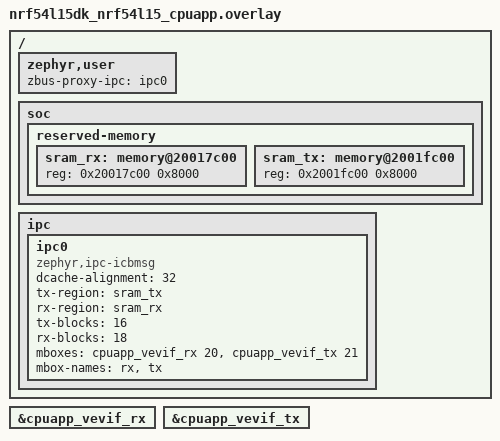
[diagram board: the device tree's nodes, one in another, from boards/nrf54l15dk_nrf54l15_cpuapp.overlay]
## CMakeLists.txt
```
#
# Copyright (c) 2026 Nordic Semiconductor ASA
#
# SPDX-License-Identifier: Apache-2.0
#

cmake_minimum_required(VERSION 3.28.0)

find_package(Zephyr REQUIRED HINTS $ENV{ZEPHYR_BASE})
project(zbus_ipc_forwarder)

zephyr_library_include_directories(src)

target_sources(app PRIVATE src/main.c)
```

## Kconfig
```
#
# Copyright (c) 2026 Nordic Semiconductor ASA
#
# SPDX-License-Identifier: Apache-2.0
#

source "Kconfig.zephyr"
```

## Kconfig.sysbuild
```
#
# Copyright (c) 2026 Nordic Semiconductor ASA
#
# SPDX-License-Identifier: Apache-2.0
#

source "share/sysbuild/Kconfig"

choice
	prompt "Remote board target"
	default REMOTE_BOARD_NRF54H20_CPURAD if BOARD = "nrf54h20dk"
	default REMOTE_BOARD_NRF54LM20A_CPUFLPR if BOARD = "nrf54lm20dk"
	default REMOTE_BOARD_NRF54L15_CPUFLPR if BOARD = "nrf54l15dk"
	default REMOTE_BOARD_NRF5340_CPUNET if BOARD = "nrf5340dk"
	default REMOTE_BOARD_ESP32_DEVKITC_ESP32_APPCPU if BOARD = "esp32_devkitc"
	default REMOTE_BOARD_ESP32S3_DEVKITC_ESP32S3_APPCPU if BOARD = "esp32s3_devkitc"

config REMOTE_BOARD_NRF54H20_CPURAD
	bool "nrf54h20dk/nrf54h20/cpurad"

config REMOTE_BOARD_NRF54LM20A_CPUFLPR
	bool "nrf54lm20dk/nrf54lm20a/cpuflpr"

config REMOTE_BOARD_NRF54L15_CPUFLPR
	bool "nrf54l15dk/nrf54l15/cpuflpr"

config REMOTE_BOARD_NRF5340_CPUNET
	bool "nrf5340dk/nrf5340/cpunet"

config REMOTE_BOARD_ESP32_DEVKITC_ESP32_APPCPU
	bool "esp32_devkitc/esp32/appcpu"

config REMOTE_BOARD_ESP32S3_DEVKITC_ESP32S3_APPCPU
	bool "esp32s3_devkitc/esp32s3/appcpu"

endchoice

config REMOTE_BOARD
	string "The board used for remote target"
	default "nrf54h20dk/nrf54h20/cpurad" if REMOTE_BOARD_NRF54H20_CPURAD
	default "nrf54l15dk/nrf54l15/cpuflpr" if REMOTE_BOARD_NRF54L15_CPUFLPR
	default "nrf54lm20dk/nrf54lm20a/cpuflpr" if REMOTE_BOARD_NRF54LM20A_CPUFLPR
	default "nrf5340dk/nrf5340/cpunet" if REMOTE_BOARD_NRF5340_CPUNET
	default "esp32_devkitc/esp32/appcpu" if REMOTE_BOARD_ESP32_DEVKITC_ESP32_APPCPU
	default "esp32s3_devkitc/esp32s3/appcpu" if REMOTE_BOARD_ESP32S3_DEVKITC_ESP32S3_APPCPU
```

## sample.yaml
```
sample:
  name: IPC Forwarder
  description: Sample application demonstrating Zbus IPC forwarder functionality.
common:
  tags:
    - zbus
  harness: console
  harness_config:
    type: multi_line
    ordered: true
    regex:
      - ".* ZBUS Proxy agent IPC Forwarder Sample Application"
      - ".* Requesting on channel request_channel, listening on channel response_channel"
      - ".* Published on channel request_channel. Test Value=1"
      - ".* Received message on channel response_channel. Test Value=2"

tests:
  sample.zbus.proxy_agent_ipc.nrf54h20_cpuapp_cpurad:
    sysbuild: true
    platform_allow:
      - nrf54h20dk/nrf54h20/cpuapp

  sample.zbus.proxy_agent_ipc.nrf54lm20_cpuapp_cpuflpr:
    sysbuild: true
    platform_allow:
      - nrf54lm20dk/nrf54lm20a/cpuapp
    extra_args:
      - proxy_agent_ipc_SNIPPET=nordic-flpr

  sample.zbus.proxy_agent_ipc.nrf54l15_cpuapp_cpuflpr:
    sysbuild: true
    platform_allow:
      - nrf54l15dk/nrf54l15/cpuapp
    extra_args:
      - proxy_agent_ipc_SNIPPET=nordic-flpr

  sample.zbus.proxy_agent_ipc.nrf5340_cpuapp_cpunet:
    sysbuild: true
    platform_allow:
      - nrf5340dk/nrf5340/cpuapp

  sample.zbus.proxy_agent_ipc.espressif:
    sysbuild: true
    platform_allow:
      - esp32_devkitc/esp32/procpu
      - esp32s3_devkitc/esp32s3/procpu
```

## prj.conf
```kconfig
#
# Copyright (c) 2026 Nordic Semiconductor ASA
#
# SPDX-License-Identifier: Apache-2.0
#

CONFIG_LOG=y

CONFIG_ZBUS=y
CONFIG_ZBUS_PROXY_AGENT=y

CONFIG_ZBUS_PROXY_AGENT_MAX_MESSAGE_SIZE=16
CONFIG_ZBUS_PROXY_AGENT_MAX_CHANNEL_NAME_SIZE=20

CONFIG_ZBUS_PROXY_AGENT_IPC=y
```

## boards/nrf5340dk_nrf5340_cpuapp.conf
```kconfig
#
# Copyright (c) 2026 Nordic Semiconductor ASA
#
# SPDX-License-Identifier: Apache-2.0
#

CONFIG_SOC_NRF53_CPUNET_ENABLE=y
```

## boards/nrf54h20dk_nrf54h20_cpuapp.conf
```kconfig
#
# Copyright (c) 2026 Nordic Semiconductor ASA
#
# SPDX-License-Identifier: Apache-2.0
#

CONFIG_SOC_NRF54H20_CPURAD_ENABLE=y
```

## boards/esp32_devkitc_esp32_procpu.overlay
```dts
/*
 * Copyright (c) 2026 Tomislav Milkovic <tomislav.milkovic95@gmail.com>
 * SPDX-License-Identifier: Apache-2.0
 */

/* Delete shm0 memory region to divide it into two parts: shm0_rx and shm0_tx */
/delete-node/ &shm0;

/ {
	zephyr,user {
		zbus-proxy-ipc = <&ipc0>;
	};

	soc {
		shm0_tx: memory@3ffe5630 {
			compatible = "mmio-sram";
			reg = <0x3ffe5630 0x2000>;
		};

		shm0_rx: memory@3ffe7630 {
			compatible = "mmio-sram";
			reg = <0x3ffe7630 0x2000>;
		};
	};

	ipc {
		ipc0: ipc0 {
			compatible = "zephyr,ipc-icbmsg";
			dcache-alignment = <32>;
			tx-region = <&shm0_tx>;
			rx-region = <&shm0_rx>;
			tx-blocks = <32>;
			rx-blocks = <32>;
			mboxes = <&mbox0 0>, <&mbox0 1>;
			mbox-names = "tx", "rx";
			status = "okay";
		};
	};
};

&mbox0 {
	status = "okay";
};
```

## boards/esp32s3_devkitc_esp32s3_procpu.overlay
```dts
/*
 * Copyright (c) 2026 Tomislav Milkovic <tomislav.milkovic95@gmail.com>
 * SPDX-License-Identifier: Apache-2.0
 */

/* Delete shm0 memory region to divide it into two parts: shm0_rx and shm0_tx */
/delete-node/ &shm0;

/ {
	zephyr,user {
		zbus-proxy-ipc = <&ipc0>;
	};

	soc {
		shm0_tx: memory@3fce5400 {
			compatible = "mmio-sram";
			reg = <0x3fce5400 0x2000>;
		};

		shm0_rx: memory@3fce7400 {
			compatible = "mmio-sram";
			reg = <0x3fce7400 0x2000>;
		};
	};

	ipc {
		ipc0: ipc0 {
			compatible = "zephyr,ipc-icbmsg";
			dcache-alignment = <32>;
			tx-region = <&shm0_tx>;
			rx-region = <&shm0_rx>;
			tx-blocks = <32>;
			rx-blocks = <32>;
			mboxes = <&mbox0 0>, <&mbox0 1>;
			mbox-names = "tx", "rx";
			status = "okay";
		};
	};
};

&mbox0 {
	status = "okay";
};
```

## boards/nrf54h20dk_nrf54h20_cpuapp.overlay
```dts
/*
 * Copyright (c) 2026 Nordic Semiconductor ASA
 *
 * SPDX-License-Identifier: Apache-2.0
 */

&cpuapp_bellboard {
	status = "okay";
};

/ {
	zephyr,user {
		zbus-proxy-ipc = <&ipc0>;
	};

	chosen {
		/delete-property/ zephyr,bt-hci;
	};
};
```

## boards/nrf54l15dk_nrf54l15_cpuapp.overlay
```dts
/*
 * Copyright (c) 2026 Nordic Semiconductor ASA
 *
 * SPDX-License-Identifier: Apache-2.0
 */

/ {
	zephyr,user {
		zbus-proxy-ipc = <&ipc0>;
	};

	soc {
		reserved-memory {
			#address-cells = <1>;
			#size-cells = <1>;

			sram_rx: memory@20017c00 {
				reg = <0x20017c00 0x8000>;
			};

			sram_tx: memory@2001fc00 {
				reg = <0x2001fc00 0x8000>;
			};
		};
	};

	ipc {
		ipc0: ipc0 {
			compatible = "zephyr,ipc-icbmsg";
			dcache-alignment = <32>;
			tx-region = <&sram_tx>;
			rx-region = <&sram_rx>;
			tx-blocks = <16>;
			rx-blocks = <18>;
			mboxes = <&cpuapp_vevif_rx 20>, <&cpuapp_vevif_tx 21>;
			mbox-names = "rx", "tx";
			status = "okay";
		};
	};
};

&cpuapp_vevif_rx {
	status = "okay";
};

&cpuapp_vevif_tx {
	status = "okay";
};
```

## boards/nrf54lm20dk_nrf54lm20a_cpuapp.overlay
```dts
/*
 * Copyright (c) 2026 Nordic Semiconductor ASA
 *
 * SPDX-License-Identifier: Apache-2.0
 */

/ {
	zephyr,user {
		zbus-proxy-ipc = <&ipc0>;
	};

	soc {
		reserved-memory {
			#address-cells = <1>;
			#size-cells = <1>;

			sram_rx: memory@20057c00 {
				reg = <0x20057c00 0x8000>;
			};

			sram_tx: memory@2005fc00 {
				reg = <0x2005fc00 0x8000>;
			};
		};
	};

	ipc {
		ipc0: ipc0 {
			compatible = "zephyr,ipc-icbmsg";
			dcache-alignment = <32>;
			tx-region = <&sram_tx>;
			rx-region = <&sram_rx>;
			tx-blocks = <16>;
			rx-blocks = <18>;
			mboxes = <&cpuapp_vevif_rx 20>, <&cpuapp_vevif_tx 21>;
			mbox-names = "rx", "tx";
			status = "okay";
		};
	};
};

&cpuapp_vevif_rx {
	status = "okay";
};

&cpuapp_vevif_tx {
	status = "okay";
};
```

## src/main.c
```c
/*
 * Copyright (c) 2026 Nordic Semiconductor ASA
 *
 * SPDX-License-Identifier: Apache-2.0
 */

#include <zephyr/kernel.h>
#include <zephyr/logging/log.h>
#include <zephyr/zbus/zbus.h>
#include <zephyr/zbus/proxy_agent/zbus_proxy_agent.h>
#include <zephyr/zbus/proxy_agent/zbus_proxy_agent_ipc.h>

LOG_MODULE_REGISTER(main, LOG_LEVEL_DBG);

/**
 * @brief Structure for the message data
 *
 * @note Must be kept in sync with the corresponding structure in the other domain to ensure correct
 * message parsing
 */
struct transfer_data {
	uint32_t test_value;
};

ZBUS_PROXY_AGENT_DEFINE(
	proxy_agent,                                     /* Proxy agent name */
	ZBUS_PROXY_AGENT_BACKEND_IPC,                    /* Proxy agent type */
	DT_PHANDLE(DT_PATH(zephyr_user), zbus_proxy_ipc) /* Backend node */
);

/**
 * Channel definitions
 * Channel request_channel is origin channel, being forwarded to domain B
 * Channel response_channel is shadow channels, shadowing channel from domain B
 */
ZBUS_CHAN_DEFINE(
	request_channel,      /* Chan name */
	struct transfer_data, /* Message type */

	NULL,                 /* Validator function */
	NULL,                 /* User data */
	ZBUS_OBSERVERS_EMPTY, /* Observers */
	ZBUS_MSG_INIT(0)      /* Initial value */
);

/* Add request channel to proxy agent forwarding */
ZBUS_PROXY_ADD_CHAN(proxy_agent, request_channel);

ZBUS_SHADOW_CHAN_DEFINE(
	response_channel,     /* Chan name */
	struct transfer_data, /* Message type */

	proxy_agent,          /* Proxy agent name */
	NULL,                 /* User data */
	ZBUS_OBSERVERS_EMPTY, /* Observers */
	ZBUS_MSG_INIT(0)      /* Initial value */
);

void ipc_forwarder_listener_cb(const struct zbus_channel *chan)
{
	const struct transfer_data *data = zbus_chan_const_msg(chan);

	LOG_INF("Received message on channel %s. Test Value=%d", chan->name, data->test_value);
}

ZBUS_LISTENER_DEFINE(ipc_forwarder_listener, ipc_forwarder_listener_cb);
ZBUS_CHAN_ADD_OBS(response_channel, ipc_forwarder_listener, 0);

int main(void)
{
	LOG_INF("ZBUS Proxy agent IPC Forwarder Sample Application");
	LOG_INF("Requesting on channel %s, listening on channel %s", request_channel.name,
		response_channel.name);

	struct transfer_data data = {.test_value = 1};

	while (1) {
		int ret;

		ret = zbus_chan_pub(&request_channel, &data, K_MSEC(100));
		if (ret < 0) {
			LOG_ERR("Failed to publish on channel %s: %d", request_channel.name, ret);
		} else {
			LOG_INF("Published on channel %s. Test Value=%d", request_channel.name,
				data.test_value);
		}

		data.test_value++;
		k_sleep(K_SECONDS(10));
	}
	return 0;
}
```
